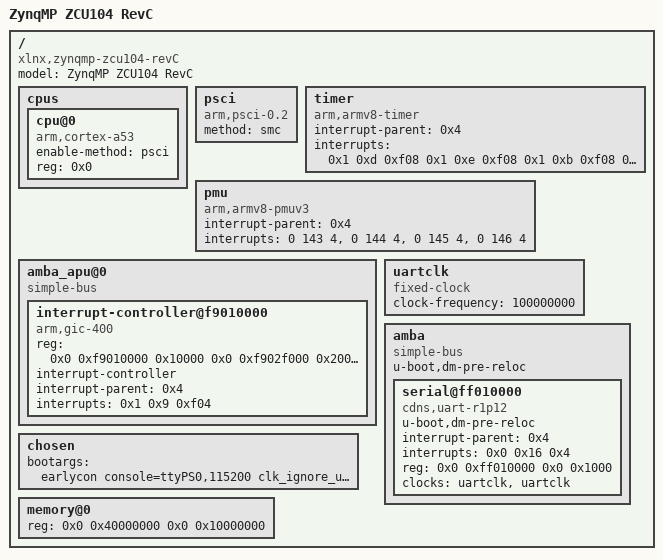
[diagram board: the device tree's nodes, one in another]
/dts-v1/;

/ {
	compatible = "xlnx,zynqmp-zcu104-revC", "xlnx,zynqmp-zcu104", "xlnx,zynqmp";
	#address-cells = <0x2>;
	#size-cells = <0x2>;
	model = "ZynqMP ZCU104 RevC";

	cpus {
		#address-cells = <0x1>;
		#size-cells = <0x0>;

		cpu@0 {
			compatible = "arm,cortex-a53", "arm,armv8";
			device_type = "cpu";
			enable-method = "psci";
			reg = <0x0>;
		};

	};
    
	psci {
		compatible = "arm,psci-0.2";
		method = "smc";
	};

	timer {
		compatible = "arm,armv8-timer";
		interrupt-parent = <0x4>;
		interrupts = <0x1 0xd 0xf08 0x1 0xe 0xf08 0x1 0xb 0xf08 0x1 0xa 0xf08>;
	};

    pmu {
        compatible = "arm,armv8-pmuv3";
        interrupt-parent = <0x4>;
        interrupts = <0 143 4>,
                 <0 144 4>,
                 <0 145 4>,
                 <0 146 4>;
    };

	amba_apu@0 {
		compatible = "simple-bus";
		#address-cells = <0x2>;
		#size-cells = <0x1>;
		ranges = <0x0 0x0 0x0 0x0 0xffffffff>;

		interrupt-controller@f9010000 {
			compatible = "arm,gic-400", "arm,cortex-a15-gic";
			#interrupt-cells = <0x3>;
			reg = <0x0 0xf9010000 0x10000 0x0 0xf902f000 0x20000 0x0 0xf9040000 0x20000 0x0 0xf9060000 0x20000>;
			interrupt-controller;
			interrupt-parent = <0x4>;
			interrupts = <0x1 0x9 0xf04>;
			phandle = <0x4>;
		};
	};

	uartclk: uartclk {
		compatible = "fixed-clock";
		#clock-cells = <0>;
		clock-frequency = <100000000>;
	};

	amba {
		compatible = "simple-bus";
		u-boot,dm-pre-reloc;
		#address-cells = <0x2>;
		#size-cells = <0x2>;
		ranges;
        
		serial@ff010000 {
			u-boot,dm-pre-reloc;
			compatible = "cdns,uart-r1p12", "xlnx,xuartps";
			status = "okay";
			interrupt-parent = <0x4>;
			interrupts = <0x0 0x16 0x4>;
			reg = <0x0 0xff010000 0x0 0x1000>;
			clock-names = "uart_clk", "pclk";
			clocks = <&uartclk>, <&uartclk>;
		};

	};

	chosen {
		bootargs = "earlycon console=ttyPS0,115200 clk_ignore_unused";
	};

	memory@0 {	
		device_type = "memory";
		reg = <0x0 0x40000000 0x0 0x10000000>;
	};
};
